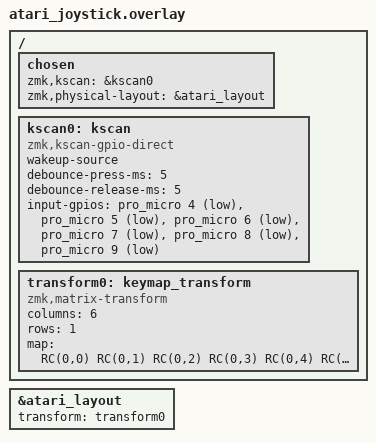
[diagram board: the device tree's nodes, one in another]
#include <dt-bindings/zmk/matrix_transform.h>
#include "atari_joystick-layouts.dtsi"

&atari_layout {
    transform = <&transform0>;
};

/ {
    chosen {
        zmk,kscan = &kscan0;
        zmk,physical-layout = &atari_layout;
    };

    kscan0: kscan {
        compatible = "zmk,kscan-gpio-direct";
        wakeup-source;
        debounce-press-ms = <5>;
        debounce-release-ms = <5>;
        input-gpios
            = <&pro_micro 4 (GPIO_ACTIVE_LOW | GPIO_PULL_UP)>   /* 022 UP    */
            , <&pro_micro 5 (GPIO_ACTIVE_LOW | GPIO_PULL_UP)>   /* 024 DOWN  */
            , <&pro_micro 6 (GPIO_ACTIVE_LOW | GPIO_PULL_UP)>   /* 100 LEFT  */
            , <&pro_micro 7 (GPIO_ACTIVE_LOW | GPIO_PULL_UP)>   /* 011 RIGHT */
            , <&pro_micro 8 (GPIO_ACTIVE_LOW | GPIO_PULL_UP)>   /* 104 FIRE  */
            , <&pro_micro 9 (GPIO_ACTIVE_LOW | GPIO_PULL_UP)>   /* 106 FN    */
            ;
    };

    transform0: keymap_transform {
        compatible = "zmk,matrix-transform";
        columns = <6>;
        rows = <1>;
        map = <
        RC(0,0)  RC(0,1)  RC(0,2)  RC(0,3)  RC(0,4)  RC(0,5)
        >;
    };
};
